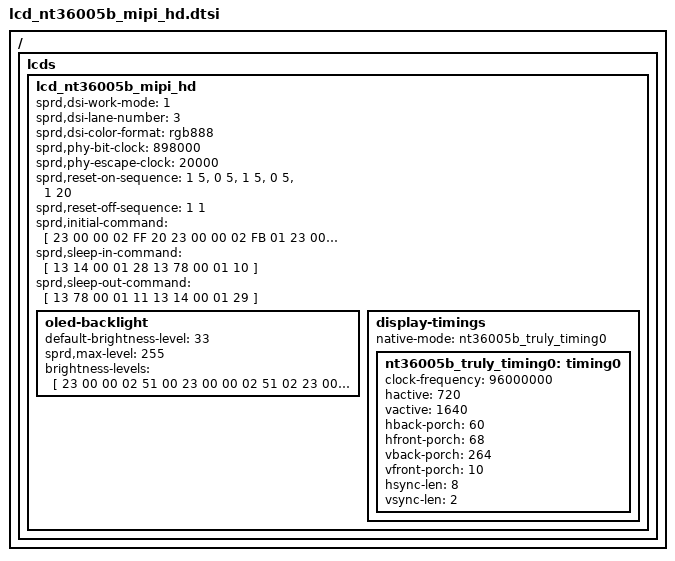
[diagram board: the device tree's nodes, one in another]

/*
 * NT36xxx  LCD config dtsi file for spreadtrum
 *
 * Copyright (C) 2018, Spreadtrum Communications Inc.
 *
 * SPDX-License-Identifier: (GPL-2.0+ OR MIT)
 */

/ {
	fragment {
		target-path = "/";
		__overlay__ {
			lcds {
				lcd_nt36005b_mipi_hd: lcd_nt36005b_mipi_hd {

					sprd,dsi-work-mode = <1>; /* video burst mode*/
					sprd,dsi-lane-number = <3>;
					sprd,dsi-color-format = "rgb888";

					sprd,phy-bit-clock = <898000>;	/* kbps */
					sprd,phy-escape-clock = <20000>;/* kHz */

					sprd,reset-on-sequence = <1 5>, <0 5>, <1 5>, <0 5>, <1 20>;
					sprd,reset-off-sequence = <1 1>;

					sprd,initial-command = [
						23 00 00 02 FF 20
						23 00 00 02 FB 01
						23 00 00 02 01 55
						23 00 00 02 03 55
						23 00 00 02 05 91
						23 00 00 02 07 4B
						23 00 00 02 08 CB
						23 00 00 02 0E 69
						23 00 00 02 0F 69
						23 00 00 02 94 C0
						23 00 00 02 95 09
						23 00 00 02 96 09
						23 00 00 02 69 91
						23 00 00 02 1F 02
						23 00 00 02 FF 20
						23 00 00 02 FB 01
						39 00 00 11 B0 00 08 00 09 00 2D 00 41 00 53 00 65 00 74 00 83
						39 00 00 11 B1 00 91 00 C5 00 ED 01 31 01 64 01 B8 01 F9 01 FC
						39 00 00 11 B2 02 3C 02 83 02 B3 02 EC 03 14 03 41 03 53 03 62
						39 00 00 0D B3 03 76 03 8C 03 A6 03 C0 03 CF 03 D1
						39 00 00 11 B4 00 08 00 09 00 2D 00 41 00 53 00 65 00 74 00 83
						39 00 00 11 B5 00 91 00 C5 00 ED 01 31 01 64 01 B8 01 F9 01 FC
						39 00 00 11 B6 02 3C 02 83 02 B3 02 EC 03 14 03 41 03 53 03 62
						39 00 00 0D B7 03 76 03 8C 03 A6 03 C0 03 CF 03 D1
						39 00 00 11 B8 00 08 00 09 00 2D 00 41 00 53 00 65 00 74 00 83
						39 00 00 11 B9 00 91 00 C5 00 ED 01 31 01 64 01 B8 01 F9 01 FC
						39 00 00 11 BA 02 3C 02 83 02 B3 02 EC 03 14 03 41 03 53 03 62
						39 00 00 0D BB 03 76 03 8C 03 A6 03 C0 03 CF 03 D1
						23 00 00 02 FF 21
						23 00 00 02 FB 01
						39 00 00 11 B0 00 00 00 01 00 25 00 39 00 4B 00 5D 00 6C 00 7B
						39 00 00 11 B1 00 89 00 BD 00 E5 01 29 01 5C 01 B0 01 F1 01 F4
						39 00 00 11 B2 02 34 02 7B 02 AB 02 E4 03 0C 03 39 03 4B 03 5A
						39 00 00 0D B3 03 6E 03 84 03 9E 03 B8 03 C7 03 C9
						39 00 00 11 B4 00 00 00 01 00 25 00 39 00 4B 00 5D 00 6C 00 7B
						39 00 00 11 B5 00 89 00 BD 00 E5 01 29 01 5C 01 B0 01 F1 01 F4
						39 00 00 11 B6 02 34 02 7B 02 AB 02 E4 03 0C 03 39 03 4B 03 5A
						39 00 00 0D B7 03 6E 03 84 03 9E 03 B8 03 C7 03 C9
						39 00 00 11 B8 00 00 00 01 00 25 00 39 00 4B 00 5D 00 6C 00 7B
						39 00 00 11 B9 00 89 00 BD 00 E5 01 29 01 5C 01 B0 01 F1 01 F4
						39 00 00 11 BA 02 34 02 7B 02 AB 02 E4 03 0C 03 39 03 4B 03 5A
						39 00 00 0D BB 03 6E 03 84 03 9E 03 B8 03 C7 03 C9
						23 00 00 02 FF 23
						23 00 00 02 FB 01
						23 00 00 02 12 B9
						23 00 00 02 15 E3
						23 00 00 02 16 0B
						23 00 00 02 FF 24
						23 00 00 02 FB 01
						23 00 00 02 93 0A
						23 00 00 02 94 12
						23 00 00 02 00 00
						23 00 00 02 01 1E
						23 00 00 02 02 1E
						23 00 00 02 03 1F
						23 00 00 02 04 1F
						23 00 00 02 05 1D
						23 00 00 02 06 1D
						23 00 00 02 07 06
						23 00 00 02 08 0C
						23 00 00 02 09 0C
						23 00 00 02 0A 0D
						23 00 00 02 0B 0D
						23 00 00 02 0C 0E
						23 00 00 02 0D 0E
						23 00 00 02 0E 0F
						23 00 00 02 0F 0F
						23 00 00 02 10 21
						23 00 00 02 11 21
						23 00 00 02 12 1C
						23 00 00 02 13 1C
						23 00 00 02 14 04
						23 00 00 02 15 05
						23 00 00 02 16 00
						23 00 00 02 17 1E
						23 00 00 02 18 1E
						23 00 00 02 19 1F
						23 00 00 02 1A 1F
						23 00 00 02 1B 1D
						23 00 00 02 1C 1D
						23 00 00 02 1D 07
						23 00 00 02 1E 0C
						23 00 00 02 1F 0C
						23 00 00 02 20 0D
						23 00 00 02 21 0D
						23 00 00 02 22 0E
						23 00 00 02 23 0E
						23 00 00 02 24 0F
						23 00 00 02 25 0F
						23 00 00 02 26 21
						23 00 00 02 27 21
						23 00 00 02 28 1C
						23 00 00 02 29 1C
						23 00 00 02 2A 04
						23 00 00 02 2B 05
						23 00 00 02 2D 0C
						23 00 00 02 41 44
						23 00 00 02 42 43
						23 00 00 02 45 43
						23 00 00 02 46 44
						23 00 00 02 47 44
						23 00 00 02 48 44
						23 00 00 02 49 00
						23 00 00 02 4A 24
						23 00 00 02 4B 91
						23 00 00 02 4C 54
						23 00 00 02 2F 0A
						23 00 00 02 30 08
						23 00 00 02 31 0E
						23 00 00 02 32 0F
						23 00 00 02 33 08
						23 00 00 02 34 0A
						23 00 00 02 35 0F
						23 00 00 02 36 0E
						23 00 00 02 37 44
						23 00 00 02 38 44
						23 00 00 02 39 00
						23 00 00 02 3A 65
						23 00 00 02 3B 8A
						23 00 00 02 3D 54
						23 00 00 02 4D 34
						23 00 00 02 4E 12
						23 00 00 02 4F 00
						23 00 00 02 50 00
						23 00 00 02 51 21
						23 00 00 02 52 43
						23 00 00 02 53 00
						23 00 00 02 54 00
						23 00 00 02 55 47
						23 00 00 02 56 44
						23 00 00 02 58 21
						23 00 00 02 59 00
						23 00 00 02 5A 65
						23 00 00 02 5B 8A
						23 00 00 02 5C 88
						23 00 00 02 5D 08
						23 00 00 02 5E 04
						23 00 00 02 5F 00
						23 00 00 02 60 80
						23 00 00 02 61 9A
						23 00 00 02 64 10
						23 00 00 02 80 0F
						23 00 00 02 81 09
						23 00 00 02 82 0F
						23 00 00 02 83 09
						23 00 00 02 84 80
						23 00 00 02 85 01
						23 00 00 02 86 04
						23 00 00 02 88 40
						23 00 00 02 89 C8
						23 00 00 02 8A 88
						23 00 00 02 8D 08
						23 00 00 02 8E 08
						23 00 00 02 91 40
						23 00 00 02 92 AE
						23 00 00 02 98 80
						23 00 00 02 AB 00
						23 00 00 02 AD 00
						23 00 00 02 AF 04
						23 00 00 02 B0 05
						23 00 00 02 B1 AA
						23 00 00 02 FF 25
						23 00 00 02 FB 01
						23 00 00 02 17 82
						23 00 00 02 18 06
						23 00 00 02 19 0F
						23 00 00 02 C0 07
						23 00 00 02 C2 84
						23 00 00 02 C6 92
						23 00 00 02 CA 1C
						23 00 00 02 CB 1C
						23 00 00 02 CC 1C
						23 00 00 02 CD 00
						23 00 00 02 CE 00
						23 00 00 02 D3 11
						23 00 00 02 D4 CC
						23 00 00 02 D5 11
						23 00 00 02 D6 1C
						23 00 00 02 D7 11
						23 00 00 02 0A 82
						23 00 00 02 0B 17
						23 00 00 02 0C 01
						23 00 00 02 FF 26
						23 00 00 02 FB 01
						23 00 00 02 00 A0
						23 00 00 02 FF 27
						23 00 00 02 FB 01
						23 00 00 02 13 00
						23 00 00 02 15 B4
						23 00 00 02 1F 55
						23 00 00 02 26 0F
						23 00 00 02 C0 18
						23 00 00 02 C1 F8
						23 00 00 02 C7 03
						23 00 00 02 C2 00
						23 00 00 02 C3 00
						23 00 00 02 C4 F8
						23 00 00 02 C5 00
						23 00 00 02 C6 00
						23 00 00 02 FF D0
						23 00 00 02 FB 01
						23 00 00 02 05 07
						23 00 00 02 09 F0
						23 00 00 02 28 70
						23 00 00 02 FF 10
						23 00 00 02 FB 01
						23 00 00 02 53 24
						23 00 00 02 55 01
						23 00 00 02 BA 02
						23 00 00 02 35 00
						23 78 00 02 11 00
						23 14 00 02 29 00
						];

					sprd,sleep-in-command = [
						13 14 00 01 28
						13 78 00 01 10
						];

					sprd,sleep-out-command = [
						13 78 00 01 11
						13 14 00 01 29
						];

					oled-backlight {
						default-brightness-level = <33>;
						sprd,max-level = <255>;

						brightness-levels = [
							23 00 00 02 51 00
							23 00 00 02 51 02
							23 00 00 02 51 02
							23 00 00 02 51 02
							23 00 00 02 51 02
							23 00 00 02 51 02
							23 00 00 02 51 03
							23 00 00 02 51 03
							23 00 00 02 51 04
							23 00 00 02 51 05
							23 00 00 02 51 07
							23 00 00 02 51 09
							23 00 00 02 51 0A
							23 00 00 02 51 0B
							23 00 00 02 51 0C
							23 00 00 02 51 0D
							23 00 00 02 51 0E
							23 00 00 02 51 0F
							23 00 00 02 51 10
							23 00 00 02 51 11
							23 00 00 02 51 12
							23 00 00 02 51 13
							23 00 00 02 51 14
							23 00 00 02 51 15
							23 00 00 02 51 16
							23 00 00 02 51 17
							23 00 00 02 51 18
							23 00 00 02 51 19
							23 00 00 02 51 1A
							23 00 00 02 51 1B
							23 00 00 02 51 1C
							23 00 00 02 51 1D
							23 00 00 02 51 1E
							23 00 00 02 51 1F
							23 00 00 02 51 20
							23 00 00 02 51 21
							23 00 00 02 51 22
							23 00 00 02 51 23
							23 00 00 02 51 24
							23 00 00 02 51 25
							23 00 00 02 51 26
							23 00 00 02 51 27
							23 00 00 02 51 28
							23 00 00 02 51 29
							23 00 00 02 51 2A
							23 00 00 02 51 2B
							23 00 00 02 51 2C
							23 00 00 02 51 2D
							23 00 00 02 51 2E
							23 00 00 02 51 2F
							23 00 00 02 51 30
							23 00 00 02 51 31
							23 00 00 02 51 32
							23 00 00 02 51 33
							23 00 00 02 51 34
							23 00 00 02 51 35
							23 00 00 02 51 36
							23 00 00 02 51 37
							23 00 00 02 51 38
							23 00 00 02 51 39
							23 00 00 02 51 3A
							23 00 00 02 51 3B
							23 00 00 02 51 3C
							23 00 00 02 51 3D
							23 00 00 02 51 3E
							23 00 00 02 51 3F
							23 00 00 02 51 40
							23 00 00 02 51 41
							23 00 00 02 51 42
							23 00 00 02 51 43
							23 00 00 02 51 44
							23 00 00 02 51 45
							23 00 00 02 51 46
							23 00 00 02 51 47
							23 00 00 02 51 48
							23 00 00 02 51 49
							23 00 00 02 51 4A
							23 00 00 02 51 4B
							23 00 00 02 51 4C
							23 00 00 02 51 4D
							23 00 00 02 51 4E
							23 00 00 02 51 4F
							23 00 00 02 51 50
							23 00 00 02 51 51
							23 00 00 02 51 52
							23 00 00 02 51 53
							23 00 00 02 51 54
							23 00 00 02 51 55
							23 00 00 02 51 56
							23 00 00 02 51 57
							23 00 00 02 51 58
							23 00 00 02 51 59
							23 00 00 02 51 5A
							23 00 00 02 51 5B
							23 00 00 02 51 5C
							23 00 00 02 51 5D
							23 00 00 02 51 5E
							23 00 00 02 51 5F
							23 00 00 02 51 60
							23 00 00 02 51 61
							23 00 00 02 51 62
							23 00 00 02 51 63
							23 00 00 02 51 64
							23 00 00 02 51 65
							23 00 00 02 51 66
							23 00 00 02 51 67
							23 00 00 02 51 68
							23 00 00 02 51 69
							23 00 00 02 51 6A
							23 00 00 02 51 6B
							23 00 00 02 51 6C
							23 00 00 02 51 6D
							23 00 00 02 51 6E
							23 00 00 02 51 6F
							23 00 00 02 51 70
							23 00 00 02 51 71
							23 00 00 02 51 72
							23 00 00 02 51 73
							23 00 00 02 51 74
							23 00 00 02 51 75
							23 00 00 02 51 76
							23 00 00 02 51 77
							23 00 00 02 51 78
							23 00 00 02 51 79
							23 00 00 02 51 7A
							23 00 00 02 51 7B
							23 00 00 02 51 7C
							23 00 00 02 51 7D
							23 00 00 02 51 7E
							23 00 00 02 51 7F
							23 00 00 02 51 80
							23 00 00 02 51 81
							23 00 00 02 51 82
							23 00 00 02 51 83
							23 00 00 02 51 84
							23 00 00 02 51 85
							23 00 00 02 51 86
							23 00 00 02 51 87
							23 00 00 02 51 88
							23 00 00 02 51 89
							23 00 00 02 51 8A
							23 00 00 02 51 8B
							23 00 00 02 51 8C
							23 00 00 02 51 8D
							23 00 00 02 51 8E
							23 00 00 02 51 8F
							23 00 00 02 51 90
							23 00 00 02 51 91
							23 00 00 02 51 92
							23 00 00 02 51 93
							23 00 00 02 51 94
							23 00 00 02 51 95
							23 00 00 02 51 96
							23 00 00 02 51 97
							23 00 00 02 51 98
							23 00 00 02 51 99
							23 00 00 02 51 9A
							23 00 00 02 51 9B
							23 00 00 02 51 9C
							23 00 00 02 51 9D
							23 00 00 02 51 9E
							23 00 00 02 51 9F
							23 00 00 02 51 A0
							23 00 00 02 51 A1
							23 00 00 02 51 A2
							23 00 00 02 51 A3
							23 00 00 02 51 A4
							23 00 00 02 51 A5
							23 00 00 02 51 A6
							23 00 00 02 51 A7
							23 00 00 02 51 A8
							23 00 00 02 51 A9
							23 00 00 02 51 AA
							23 00 00 02 51 AB
							23 00 00 02 51 AC
							23 00 00 02 51 AD
							23 00 00 02 51 AE
							23 00 00 02 51 AF
							23 00 00 02 51 B0
							23 00 00 02 51 B1
							23 00 00 02 51 B2
							23 00 00 02 51 B3
							23 00 00 02 51 B4
							23 00 00 02 51 B5
							23 00 00 02 51 B6
							23 00 00 02 51 B7
							23 00 00 02 51 B8
							23 00 00 02 51 B9
							23 00 00 02 51 BA
							23 00 00 02 51 BB
							23 00 00 02 51 BC
							23 00 00 02 51 BD
							23 00 00 02 51 BE
							23 00 00 02 51 BF
							23 00 00 02 51 C0
							23 00 00 02 51 C1
							23 00 00 02 51 C2
							23 00 00 02 51 C3
							23 00 00 02 51 C4
							23 00 00 02 51 C5
							23 00 00 02 51 C6
							23 00 00 02 51 C7
							23 00 00 02 51 C8
							23 00 00 02 51 C9
							23 00 00 02 51 CA
							23 00 00 02 51 CB
							23 00 00 02 51 CC
							23 00 00 02 51 CD
							23 00 00 02 51 CE
							23 00 00 02 51 CF
							23 00 00 02 51 D0
							23 00 00 02 51 D1
							23 00 00 02 51 D2
							23 00 00 02 51 D3
							23 00 00 02 51 D4
							23 00 00 02 51 D5
							23 00 00 02 51 D6
							23 00 00 02 51 D7
							23 00 00 02 51 D8
							23 00 00 02 51 D9
							23 00 00 02 51 DA
							23 00 00 02 51 DB
							23 00 00 02 51 DC
							23 00 00 02 51 DD
							23 00 00 02 51 DE
							23 00 00 02 51 DF
							23 00 00 02 51 E0
							23 00 00 02 51 E1
							23 00 00 02 51 E2
							23 00 00 02 51 E3
							23 00 00 02 51 E4
							23 00 00 02 51 E5
							23 00 00 02 51 E6
							23 00 00 02 51 E7
							23 00 00 02 51 E8
							23 00 00 02 51 E9
							23 00 00 02 51 EA
							23 00 00 02 51 EB
							23 00 00 02 51 EC
							23 00 00 02 51 ED
							23 00 00 02 51 EE
							23 00 00 02 51 EF
							23 00 00 02 51 F0
							23 00 00 02 51 F1
							23 00 00 02 51 F2
							23 00 00 02 51 F3
							23 00 00 02 51 F4
							23 00 00 02 51 F5
							23 00 00 02 51 F6
							23 00 00 02 51 F7
							23 00 00 02 51 F8
							23 00 00 02 51 F9
							23 00 00 02 51 FA
							23 00 00 02 51 FB
							23 00 00 02 51 FC
							23 00 00 02 51 FD
							23 00 00 02 51 FE
							];
						};

					display-timings {
						native-mode = <&nt36005b_truly_timing0>;

						nt36005b_truly_timing0: timing0 {
							clock-frequency = <96000000>;
							hactive = <720>;
							vactive = <1640>;
							hback-porch = <60>;
							hfront-porch = <68>;
							vback-porch = <264>;
							vfront-porch = <10>;
							hsync-len = <8>;
							vsync-len = <2>;
						};
					};
				};
			};
		};
	};
};
